# GD32H7xx register map
File version: 1.0
CPU: CM7 r1p2, little endian, MPU, FPU, 4 interrupt priority bits
Registers are 32-bit, read-write, reset 0x0 unless marked. A register's access mark holds for its fields unless they carry their own. Offsets are from the block's base; [hi:lo] are bit positions; {n}, {i} and the like mark numbered series.

## FMC — Flash memory controller
Base 0x52002000
0x04 KEY wo — Unlock key register
  [31:0] KEY — FMC_CTL unlock register
0x08 OBKEY wo — Option byte unlock key register
  [31:0] OBKEY — These bits are only be written by software
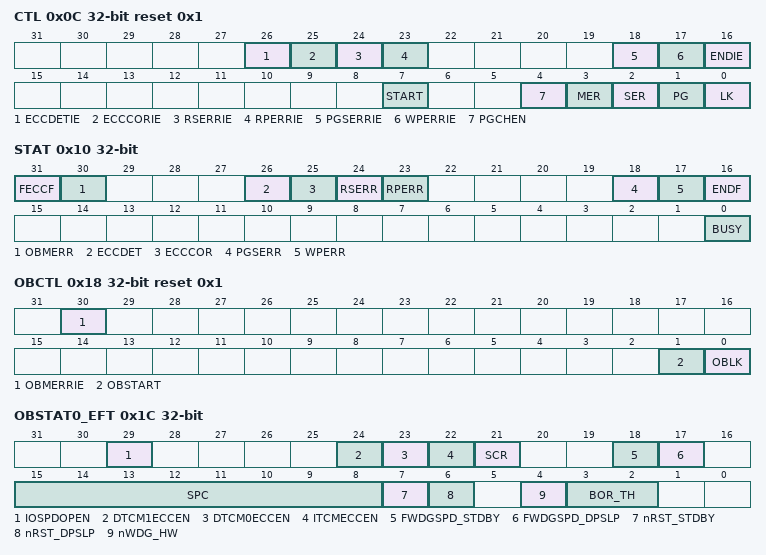
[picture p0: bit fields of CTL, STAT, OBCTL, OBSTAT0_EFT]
0x0C CTL access per field reset 0x1 — Control register
  [26] ECCDETIE rw — Two bit errors detect interrupt enable
  [25] ECCCORIE rw — One bit error correct interrupt enable
  [24] RSERRIE rw — Read secure error interrupt enable
  [23] RPERRIE rw — Read protection error interrupt enable
  [18] PGSERRIE rw — Program sequence error interrupt enable
  [17] WPERRIE rw — Erase/program protection error interrupt enable
  [16] ENDIE rw — End of operation interrupt enable
  [7] START ro — Send erase command to FMC
  [4] PGCHEN rw — Check programming area enable
  [3] MER rw — Mass erase command bit
  [2] SER rw — Sector erase command bit
  [1] PG rw — Main Flash program command bit
  [0] LK ro — FMC_CTL lock bit
0x10 STAT access per field — Status register
  [31] FECCF rw — Flash ECC function flag
  [30] OBMERR rw — Option byte modify error flag
  [26] ECCDET rw — Two bit errors detect flag
  [25] ECCCOR rw — One bit error detected and correct flag
  [24] RSERR rw — Read secure error flag bit
  [23] RPERR rw — Read protection error flag bit
  [18] PGSERR rw — Program sequence error flag bit
  [17] WPERR rw — Erase/program protection error flag bit
  [16] ENDF rw — End of operation flag bit
  [0] BUSY ro — The Flash is busy bit
0x14 ADDR — Address register
  [31:0] ADDR — Flash erase command address bits
0x18 OBCTL access per field reset 0x1 — Option byte control register
  [30] OBMERRIE rw — Option byte modify error interrupt enable
  [1] OBSTART ro — Send option byte change command to FMC bit
  [0] OBLK ro — FMC_OBCTL lock bit
0x1C OBSTAT0_EFT ro — Option byte status register 0
  [29] IOSPDOPEN — I/O speed optimization, High-speed at low-voltage enable status bit
  [24] DTCM1ECCEN — DTCM1 ECC function enable status bit
  [23] DTCM0ECCEN — DTCM0 ECC function enable status bit
  [22] ITCMECCEN — ITCM ECC function enable status bit
  [21] SCR — Secure access mode status bit
  [18] FWDGSPD_STDBY — FWDGT suspend option in standby mode status bit
  [17] FWDGSPD_DPSLP — FWDGT suspend option in deepsleep mode status bit
  [15:8] SPC — Security protection level option byte status bits
  [7] nRST_STDBY — Option byte standby reset status bit
  [6] nRST_DPSLP — Option byte deepsleep reset status bit
  [4] nWDG_HW — Watchdog status bit
  [3:2] BOR_TH — BOR threshold status bits
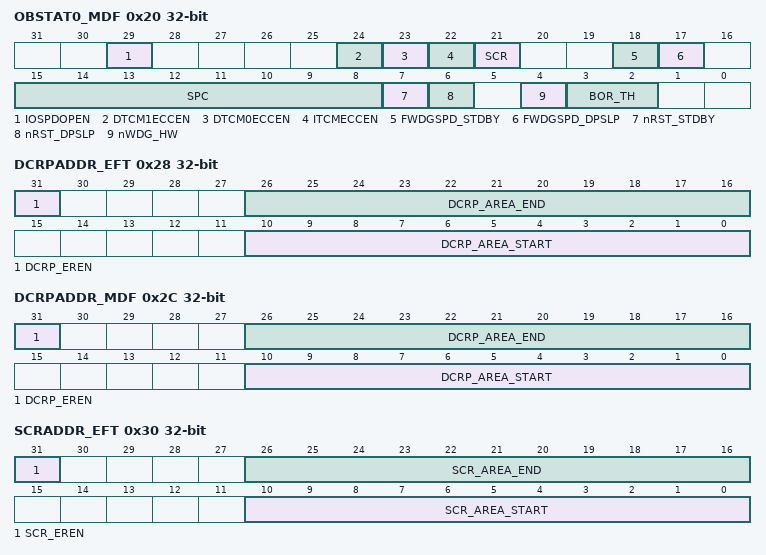
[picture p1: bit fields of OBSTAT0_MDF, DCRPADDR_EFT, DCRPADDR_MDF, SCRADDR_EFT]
0x20 OBSTAT0_MDF — Option byte status register 0
  [29] IOSPDOPEN — I/O speed optimization, High-speed at low-voltage enable configuration bit
  [24] DTCM1ECCEN — DTCM1 ECC function enable configuration bit
  [23] DTCM0ECCEN — DTCM0 ECC function enable configuration bit
  [22] ITCMECCEN — ITCM ECC function enable configuration bit
  [21] SCR — Secure access mode configuration bit
  [18] FWDGSPD_STDBY — FWDGT suspend option in standby mode configuration bit
  [17] FWDGSPD_DPSLP — FWDGT suspend option in deepsleep mode configuration bit
  [15:8] SPC — Security protection level option configuration bits
  [7] nRST_STDBY — Option byte standby reset configuration bit
  [6] nRST_DPSLP — Option byte deepsleep reset configuration bit
  [4] nWDG_HW — Watchdog configuration bit
  [3:2] BOR_TH — BOR threshold configuration bits
0x28 DCRPADDR_EFT ro — DCRP address register
  [31] DCRP_EREN — DCRP area erase enable status bit
  [26:16] DCRP_AREA_END — DCRP area end address status bits
  [10:0] DCRP_AREA_START — DCRP area start address status bits
0x2C DCRPADDR_MDF — DCRP address register
  [31] DCRP_EREN — DCRP area erase enable configuration bit
  [26:16] DCRP_AREA_END — DCRP area end address configuration bits
  [10:0] DCRP_AREA_START — DCRP area start address configuration bits
0x30 SCRADDR_EFT ro — Secure address register
  [31] SCR_EREN — Secure access area erase enable option status bit
  [26:16] SCR_AREA_END — Secure-access area end address status bits
  [10:0] SCR_AREA_START — Secure-access area start address status bits
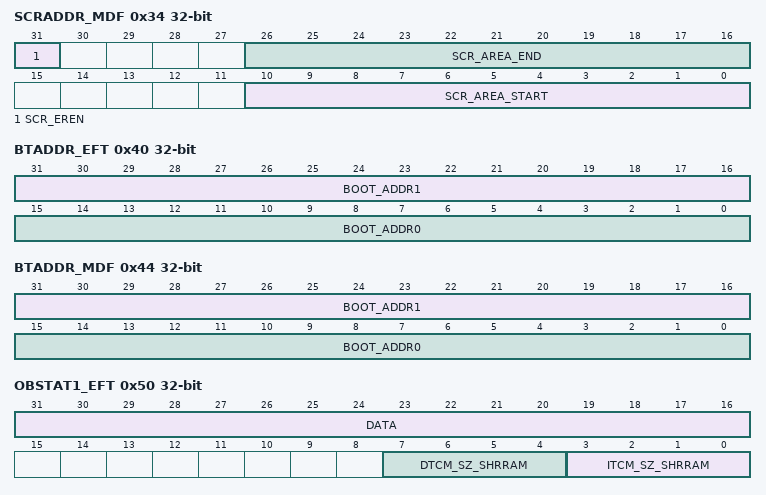
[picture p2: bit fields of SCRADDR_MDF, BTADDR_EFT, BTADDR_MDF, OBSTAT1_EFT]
0x34 SCRADDR_MDF access per field — Secure address register
  [31] SCR_EREN rw — Secure access area erase enable option configuration bit
  [26:16] SCR_AREA_END ro — Secure-access area end address configuration bits
  [10:0] SCR_AREA_START ro — Secure-access area start address configuration bits
0x38 WP_EFT ro — Erase/program protection register
  [29:0] WP — Sector erase/program protection option status bit
0x3C WP_MDF — Erase/program protection register
  [29:0] WP — Sector erase/program protection option configuration bit
0x40 BTADDR_EFT ro — Boot address register
  [31:16] BOOT_ADDR1 — Boot address 1 status bits
  [15:0] BOOT_ADDR0 — Boot address 0 status bits
0x44 BTADDR_MDF — Boot address register
  [31:16] BOOT_ADDR1 — Boot address 1 configuration bits
  [15:0] BOOT_ADDR0 — Boot address 0 configuration bits
0x50 OBSTAT1_EFT ro — Option byte status register 1
  [31:16] DATA — User defined option byte data status value
  [7:4] DTCM_SZ_SHRRAM — DTCM size of shared RAM status bits
  [3:0] ITCM_SZ_SHRRAM — ITCM size of shared RAM status bits
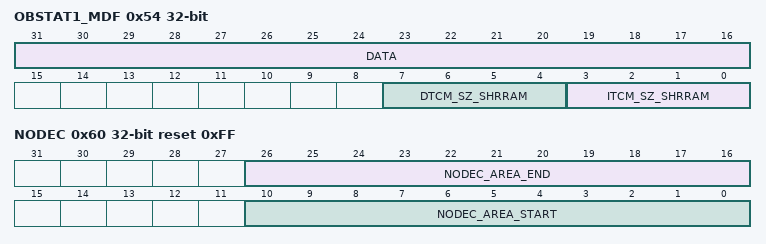
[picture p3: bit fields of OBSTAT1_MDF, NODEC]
0x54 OBSTAT1_MDF — Option byte status register 1
  [31:16] DATA — User defined option byte data configuration value
  [7:4] DTCM_SZ_SHRRAM — DTCM size of shared RAM configuration bits
  [3:0] ITCM_SZ_SHRRAM — ITCM size of shared RAM configuration bits
0x60 NODEC reset 0xFF — NO-RTDEC area register
  [26:16] NODEC_AREA_END — NO-RTDEC area end address
  [10:0] NODEC_AREA_START — No-RTDEC area start address
{0x68+4i} AESIV{i}_EFT ro (i=0..2) — AES IV{i} register
  [31:0] AESIV — AES initialization vector status value
0x74 AESIV0_MDF ro — AES IV0 register
  [31:0] AESIV — AES initialization vector configuration value
0x78 AESIV1_MDF ro — AES IV1 register
  [31:0] AESIV — AES initialization vector status value
0x7C AESIV2_MDF ro — AES IV2 register
  [31:0] AESIV — AES initialization vector status value
0x100 PID0 ro — Product ID register 0
  [31:0] PID0 — Product reserved ID code register x
0x104 PID1 ro — Product ID register 1
  [31:0] PID1 — Product reserved ID code register x
